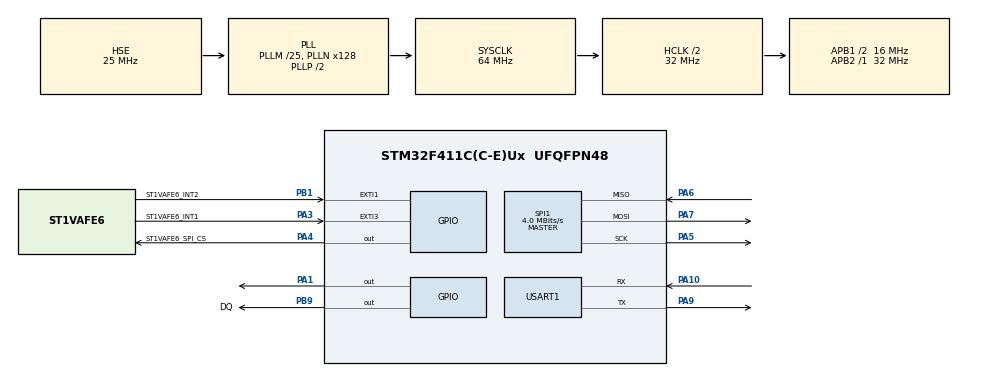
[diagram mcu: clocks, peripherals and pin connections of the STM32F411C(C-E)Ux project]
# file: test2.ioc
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FREERTOS.Tasks01=LED,0,128,LED_Task,As weak,NULL,Dynamic,NULL,NULL;myTask02,-3,128,StartTask02,As external,NULL,Dynamic,NULL,NULL
Mcu.Family=STM32F4
Mcu.Name=STM32F411C(C-E)Ux
Mcu.Package=UFQFPN48
NVIC.EXTI1_IRQn=true\:5\:0\:false\:false\:true\:true\:true\:true\:true
NVIC.EXTI3_IRQn=true\:5\:0\:false\:false\:true\:true\:true\:true\:true
NVIC.PriorityGroup=NVIC_PRIORITYGROUP_4
PA1.PinState=GPIO_PIN_SET
PA1.Signal=GPIO_Output
PA10.Mode=Asynchronous
PA10.Signal=USART1_RX
PA13.Mode=Serial_Wire
PA13.Signal=SYS_JTMS-SWDIO
PA14.Mode=Serial_Wire
PA14.Signal=SYS_JTCK-SWCLK
PA3.GPIO_Label=ST1VAFE6_INT1
PA3.GPIO_PuPd=GPIO_PULLUP
PA3.Signal=GPXTI3
PA4.GPIO_Label=ST1VAFE6_SPI_CS
PA4.Signal=GPIO_Output
PA5.Mode=Full_Duplex_Master
PA5.Signal=SPI1_SCK
PA6.Mode=Full_Duplex_Master
PA6.Signal=SPI1_MISO
PA7.Mode=Full_Duplex_Master
PA7.Signal=SPI1_MOSI
PA9.Mode=Asynchronous
PA9.Signal=USART1_TX
PB1.GPIO_Label=ST1VAFE6_INT2
PB1.GPIO_PuPd=GPIO_PULLUP
PB1.Signal=GPXTI1
PB9.GPIO_Label=DQ
PB9.Signal=GPIO_Output
PC14-OSC32_IN.Mode=LSE-External-Oscillator
PC14-OSC32_IN.Signal=RCC_OSC32_IN
PC15-OSC32_OUT.Mode=LSE-External-Oscillator
PC15-OSC32_OUT.Signal=RCC_OSC32_OUT
PH0\ -\ OSC_IN.Mode=HSE-External-Oscillator
PH0\ -\ OSC_IN.Signal=RCC_OSC_IN
PH1\ -\ OSC_OUT.Mode=HSE-External-Oscillator
PH1\ -\ OSC_OUT.Signal=RCC_OSC_OUT
ProjectManager.HeapSize=0x200
ProjectManager.StackSize=0x400
ProjectManager.TargetToolchain=CMake
RCC.48MHZClocksFreq_Value=32000000
RCC.AHBCLKDivider=RCC_SYSCLK_DIV2
RCC.AHBFreq_Value=32000000
RCC.APB1CLKDivider=RCC_HCLK_DIV2
RCC.APB1Freq_Value=16000000
RCC.APB1TimFreq_Value=32000000
RCC.APB2Freq_Value=32000000
RCC.APB2TimFreq_Value=32000000
RCC.CortexFreq_Value=32000000
RCC.HCLKFreq_Value=32000000
RCC.HSE_VALUE=25000000
RCC.HSI_VALUE=16000000
RCC.PLLM=25
RCC.PLLN=128
RCC.PLLSourceVirtual=RCC_PLLSOURCE_HSE
RCC.SYSCLKFreq_VALUE=64000000
RCC.SYSCLKSource=RCC_SYSCLKSOURCE_PLLCLK
RCC.VCOOutputFreq_Value=128000000
SPI1.BaudRatePrescaler=SPI_BAUDRATEPRESCALER_8
SPI1.CalculateBaudRate=4.0 MBits/s
SPI1.Direction=SPI_DIRECTION_2LINES
SPI1.Mode=SPI_MODE_MASTER
SPI1.VirtualType=VM_MASTER
USART1.VirtualMode=VM_ASYNC
VP_FREERTOS_VS_CMSIS_V1.Mode=CMSIS_V1
board=custom

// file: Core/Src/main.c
/* USER CODE BEGIN Header */
/**
  ******************************************************************************
  * @file           : main.c
  * @brief          : Main program body
  ******************************************************************************
  * @attention
  *
  * Copyright (c) 2026 STMicroelectronics.
  * All rights reserved.
  *
  * This software is licensed under terms that can be found in the LICENSE file
  * in the root directory of this software component.
  * If no LICENSE file comes with this software, it is provided AS-IS.
  *
  ******************************************************************************
  */
/* USER CODE END Header */
#include "main.h"
#include "cmsis_os.h"

/* USER CODE BEGIN Includes */
#include "DS18B20.h"
#include "ST1VAFE.h"
#include "stm32f411xe.h"
#include "stm32f4xx_hal_gpio.h"
/* USER CODE END Includes */

SPI_HandleTypeDef hspi1;

UART_HandleTypeDef huart1;

osThreadId LEDHandle;
osThreadId myTask02Handle;

void SystemClock_Config(void);
static void MX_GPIO_Init(void);
static void MX_SPI1_Init(void);
static void MX_USART1_UART_Init(void);
void LED_Task(void const * argument);
extern void StartTask02(void const * argument);

/* USER CODE BEGIN PFP */
void DWT_Init(void) {
    CoreDebug->DEMCR |= CoreDebug_DEMCR_TRCENA_Msk;
    DWT->CTRL |= DWT_CTRL_CYCCNTENA_Msk;
    DWT->CYCCNT = 0;
}

/* USER CODE END PFP */

int main(void)
{

  /* MCU Configuration--------------------------------------------------------*/

  /* Reset of all peripherals, Initializes the Flash interface and the Systick. */
  HAL_Init();

  /* Configure the system clock */
  SystemClock_Config();

  /* Initialize all configured peripherals */
  MX_GPIO_Init();
  MX_SPI1_Init();
  MX_USART1_UART_Init();
  /* USER CODE BEGIN 2 */
    ST1VAFE6AX_Init();
  /* USER CODE END 2 */

  /* Create the thread(s) */
  /* definition and creation of LED */
  osThreadDef(LED, LED_Task, osPriorityNormal, 0, 128);
  LEDHandle = osThreadCreate(osThread(LED), NULL);

  /* definition and creation of myTask02 */
  osThreadDef(myTask02, StartTask02, osPriorityIdle, 0, 128);
  myTask02Handle = osThreadCreate(osThread(myTask02), NULL);

  /* Start scheduler */
  osKernelStart();

  /* We should never get here as control is now taken by the scheduler */

  /* Infinite loop */
  while (1)
  {

  }
}

void SystemClock_Config(void)
{
  RCC_OscInitTypeDef RCC_OscInitStruct = {0};
  RCC_ClkInitTypeDef RCC_ClkInitStruct = {0};

  /** Configure the main internal regulator output voltage
  */
  __HAL_RCC_PWR_CLK_ENABLE();
  __HAL_PWR_VOLTAGESCALING_CONFIG(PWR_REGULATOR_VOLTAGE_SCALE1);

  /** Initializes the RCC Oscillators according to the specified parameters
  * in the RCC_OscInitTypeDef structure.
  */
  RCC_OscInitStruct.OscillatorType = RCC_OSCILLATORTYPE_HSE;
  RCC_OscInitStruct.HSEState = RCC_HSE_ON;
  RCC_OscInitStruct.PLL.PLLState = RCC_PLL_ON;
  RCC_OscInitStruct.PLL.PLLSource = RCC_PLLSOURCE_HSE;
  RCC_OscInitStruct.PLL.PLLM = 25;
  RCC_OscInitStruct.PLL.PLLN = 128;
  RCC_OscInitStruct.PLL.PLLP = RCC_PLLP_DIV2;
  RCC_OscInitStruct.PLL.PLLQ = 4;
  if (HAL_RCC_OscConfig(&RCC_OscInitStruct) != HAL_OK)
  {
    Error_Handler();
  }

  /** Initializes the CPU, AHB and APB buses clocks
  */
  RCC_ClkInitStruct.ClockType = RCC_CLOCKTYPE_HCLK|RCC_CLOCKTYPE_SYSCLK
                              |RCC_CLOCKTYPE_PCLK1|RCC_CLOCKTYPE_PCLK2;
  RCC_ClkInitStruct.SYSCLKSource = RCC_SYSCLKSOURCE_PLLCLK;
  RCC_ClkInitStruct.AHBCLKDivider = RCC_SYSCLK_DIV2;
  RCC_ClkInitStruct.APB1CLKDivider = RCC_HCLK_DIV2;
  RCC_ClkInitStruct.APB2CLKDivider = RCC_HCLK_DIV1;

  if (HAL_RCC_ClockConfig(&RCC_ClkInitStruct, FLASH_LATENCY_1) != HAL_OK)
  {
    Error_Handler();
  }
}

static void MX_SPI1_Init(void)
{

  /* SPI1 parameter configuration*/
  hspi1.Instance = SPI1;
  hspi1.Init.Mode = SPI_MODE_MASTER;
  hspi1.Init.Direction = SPI_DIRECTION_2LINES;
  hspi1.Init.DataSize = SPI_DATASIZE_8BIT;
  hspi1.Init.CLKPolarity = SPI_POLARITY_LOW;
  hspi1.Init.CLKPhase = SPI_PHASE_1EDGE;
  hspi1.Init.NSS = SPI_NSS_SOFT;
  hspi1.Init.BaudRatePrescaler = SPI_BAUDRATEPRESCALER_8;
  hspi1.Init.FirstBit = SPI_FIRSTBIT_MSB;
  hspi1.Init.TIMode = SPI_TIMODE_DISABLE;
  hspi1.Init.CRCCalculation = SPI_CRCCALCULATION_DISABLE;
  hspi1.Init.CRCPolynomial = 10;
  if (HAL_SPI_Init(&hspi1) != HAL_OK)
  {
    Error_Handler();
  }

}

static void MX_USART1_UART_Init(void)
{

  huart1.Instance = USART1;
  huart1.Init.BaudRate = 115200;
  huart1.Init.WordLength = UART_WORDLENGTH_8B;
  huart1.Init.StopBits = UART_STOPBITS_1;
  huart1.Init.Parity = UART_PARITY_NONE;
  huart1.Init.Mode = UART_MODE_TX_RX;
  huart1.Init.HwFlowCtl = UART_HWCONTROL_NONE;
  huart1.Init.OverSampling = UART_OVERSAMPLING_16;
  if (HAL_UART_Init(&huart1) != HAL_OK)
  {
    Error_Handler();
  }

}

static void MX_GPIO_Init(void)
{
  GPIO_InitTypeDef GPIO_InitStruct = {0};

  /* GPIO Ports Clock Enable */
  __HAL_RCC_GPIOC_CLK_ENABLE();
  __HAL_RCC_GPIOH_CLK_ENABLE();
  __HAL_RCC_GPIOA_CLK_ENABLE();
  __HAL_RCC_GPIOB_CLK_ENABLE();

  /*Configure GPIO pin Output Level */
  HAL_GPIO_WritePin(GPIOA, GPIO_PIN_1, GPIO_PIN_SET);

  /*Configure GPIO pin Output Level */
  HAL_GPIO_WritePin(ST1VAFE6_SPI_CS_GPIO_Port, ST1VAFE6_SPI_CS_Pin, GPIO_PIN_RESET);

  /*Configure GPIO pin Output Level */
  HAL_GPIO_WritePin(DQ_GPIO_Port, DQ_Pin, GPIO_PIN_RESET);

  /*Configure GPIO pins : PA1 ST1VAFE6_SPI_CS_Pin */
  GPIO_InitStruct.Pin = GPIO_PIN_1|ST1VAFE6_SPI_CS_Pin;
  GPIO_InitStruct.Mode = GPIO_MODE_OUTPUT_PP;
  GPIO_InitStruct.Pull = GPIO_NOPULL;
  GPIO_InitStruct.Speed = GPIO_SPEED_FREQ_LOW;
  HAL_GPIO_Init(GPIOA, &GPIO_InitStruct);

  /*Configure GPIO pin : ST1VAFE6_INT1_Pin */
  GPIO_InitStruct.Pin = ST1VAFE6_INT1_Pin;
  GPIO_InitStruct.Mode = GPIO_MODE_IT_RISING;
  GPIO_InitStruct.Pull = GPIO_PULLUP;
  HAL_GPIO_Init(ST1VAFE6_INT1_GPIO_Port, &GPIO_InitStruct);

  /*Configure GPIO pin : ST1VAFE6_INT2_Pin */
  GPIO_InitStruct.Pin = ST1VAFE6_INT2_Pin;
  GPIO_InitStruct.Mode = GPIO_MODE_IT_RISING;
  GPIO_InitStruct.Pull = GPIO_PULLUP;
  HAL_GPIO_Init(ST1VAFE6_INT2_GPIO_Port, &GPIO_InitStruct);

  /*Configure GPIO pin : DQ_Pin */
  GPIO_InitStruct.Pin = DQ_Pin;
  GPIO_InitStruct.Mode = GPIO_MODE_OUTPUT_PP;
  GPIO_InitStruct.Pull = GPIO_NOPULL;
  GPIO_InitStruct.Speed = GPIO_SPEED_FREQ_LOW;
  HAL_GPIO_Init(DQ_GPIO_Port, &GPIO_InitStruct);

  /* EXTI interrupt init*/
  HAL_NVIC_SetPriority(EXTI1_IRQn, 5, 0);
  HAL_NVIC_EnableIRQ(EXTI1_IRQn);

  HAL_NVIC_SetPriority(EXTI3_IRQn, 5, 0);
  HAL_NVIC_EnableIRQ(EXTI3_IRQn);

}

__weak void LED_Task(void const * argument)
{
  for(;;)
  {
    osDelay(1);
  }
}

void Error_Handler(void)
{
  __disable_irq();
  while (1)
  {
  }
}
